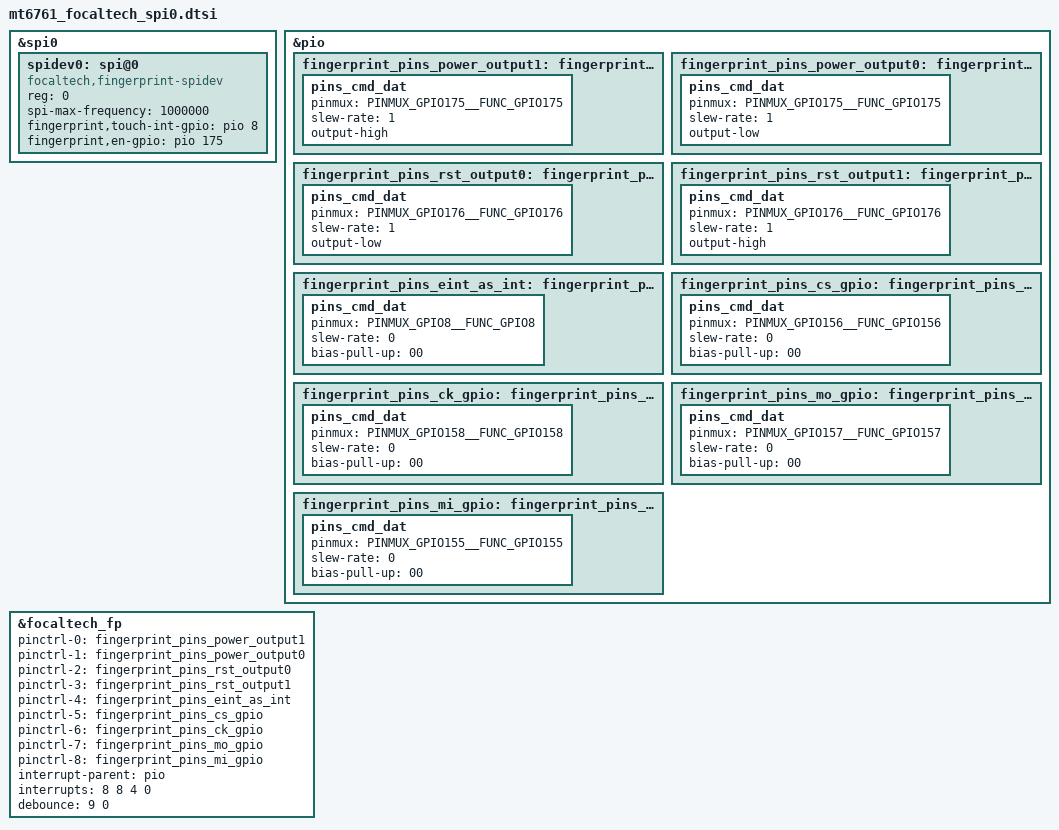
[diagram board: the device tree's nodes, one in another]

/*Start added by focaltech for fingerprint*/
&spi0{
      status = "okay";
      #address-cells = <1> ;
      #size-cells = <0> ;
      spidev0: spi@0 {
          compatible = "focaltech,fingerprint-spidev";
          reg = <0>;
          spi-max-frequency = <1000000>;                  
          fingerprint,touch-int-gpio = <&pio 8 0>;
          fingerprint,en-gpio = <&pio 175 0>;                   
          status = "okay";
	  };
};


&pio {
	fingerprint_pins_power_output1:fingerprint_pins_power_output1@1{
		    pins_cmd_dat {
			pinmux = <PINMUX_GPIO175__FUNC_GPIO175>;
			slew-rate = <1>;
			output-high;
		};
	};

	fingerprint_pins_power_output0:fingerprint_pins_power_output0@0{
		    pins_cmd_dat {
			pinmux = <PINMUX_GPIO175__FUNC_GPIO175>;
			slew-rate = <1>;
			output-low;
		};
	};
	fingerprint_pins_rst_output0:fingerprint_pins_rst_output0@0{
		    pins_cmd_dat {
			pinmux = <PINMUX_GPIO176__FUNC_GPIO176>;
			slew-rate = <1>;
			output-low;
		};
	};
	fingerprint_pins_rst_output1:fingerprint_pins_rst_output1@1{
		    pins_cmd_dat {
			pinmux = <PINMUX_GPIO176__FUNC_GPIO176>;
			slew-rate = <1>;
			output-high;
		};
	};
	fingerprint_pins_eint_as_int: fingerprint_pins_eint_as_int@0{
		pins_cmd_dat {
			pinmux = <PINMUX_GPIO8__FUNC_GPIO8>;
			slew-rate = <0>;
			bias-pull-up = <00>;
		};
	};
	
	fingerprint_pins_cs_gpio: fingerprint_pins_cs_gpio@0{
		pins_cmd_dat {
			pinmux = <PINMUX_GPIO156__FUNC_GPIO156>;
			slew-rate = <0>;
			bias-pull-up = <00>;
		};
	};
	
	fingerprint_pins_ck_gpio: fingerprint_pins_ck_gpio@0{
		pins_cmd_dat {
			pinmux = <PINMUX_GPIO158__FUNC_GPIO158>;
			slew-rate = <0>;
			bias-pull-up = <00>;
		};
	};
	
	fingerprint_pins_mo_gpio: fingerprint_pins_mo_gpio@0{
		pins_cmd_dat {
			pinmux = <PINMUX_GPIO157__FUNC_GPIO157>;
			slew-rate = <0>;
			bias-pull-up = <00>;
		};
	};
	
	fingerprint_pins_mi_gpio: fingerprint_pins_mi_gpio@0{
		pins_cmd_dat {
			pinmux = <PINMUX_GPIO155__FUNC_GPIO155>;
			slew-rate = <0>;
			bias-pull-up = <00>;
		};
	};
};

&focaltech_fp{
	pinctrl-names ="fpsensor_finger_power_high","fpsensor_finger_power_low","fpsensor_finger_rst_low","fpsensor_finger_rst_high","fpsensor_eint_as_int","fpsensor_cs_to_gpio","fpsensor_ck_to_gpio","fpsensor_mo_to_gpio","fpsensor_mi_to_gpio";
	
	pinctrl-0 = <&fingerprint_pins_power_output1>;
	pinctrl-1 = <&fingerprint_pins_power_output0>;
	pinctrl-2 = <&fingerprint_pins_rst_output0>;
	pinctrl-3 = <&fingerprint_pins_rst_output1>;
        pinctrl-4 = <&fingerprint_pins_eint_as_int>;
	pinctrl-5 = <&fingerprint_pins_cs_gpio>;
	pinctrl-6 = <&fingerprint_pins_ck_gpio>;
	pinctrl-7 = <&fingerprint_pins_mo_gpio>;
        pinctrl-8 = <&fingerprint_pins_mi_gpio>;
	
	interrupt-parent = <&pio>;
	interrupts = <8 8 4 0>;
	debounce = <9 0>;
	status = "okay";
};
/*End added by focaltech for fingerprint*/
